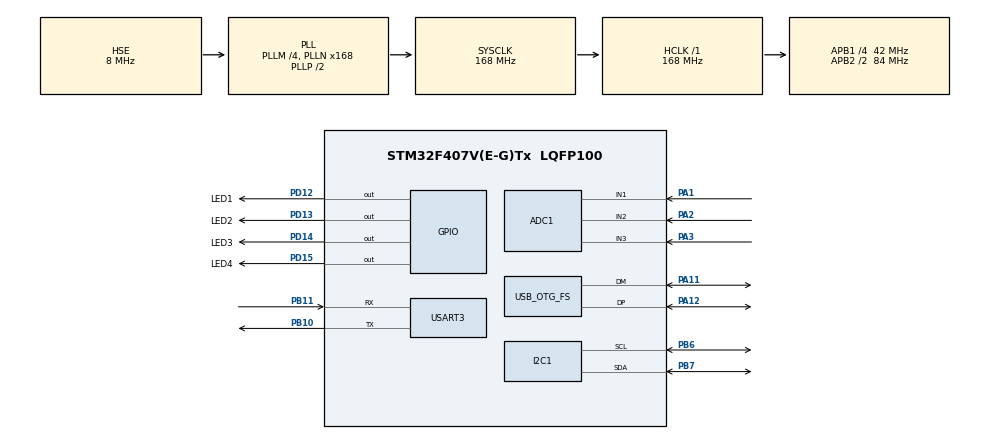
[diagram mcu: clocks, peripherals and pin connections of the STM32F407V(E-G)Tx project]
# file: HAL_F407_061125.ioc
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ADC1.Channel-0\#ChannelRegularConversion=ADC_CHANNEL_1
ADC1.Channel-1\#ChannelRegularConversion=ADC_CHANNEL_2
ADC1.Channel-2\#ChannelRegularConversion=ADC_CHANNEL_3
ADC1.ContinuousConvMode=ENABLE
ADC1.DMAContinuousRequests=ENABLE
ADC1.NbrOfConversion=3
ADC1.NbrOfConversionFlag=1
ADC1.Rank-0\#ChannelRegularConversion=1
ADC1.Rank-1\#ChannelRegularConversion=2
ADC1.Rank-2\#ChannelRegularConversion=3
ADC1.SamplingTime-0\#ChannelRegularConversion=ADC_SAMPLETIME_144CYCLES
ADC1.SamplingTime-1\#ChannelRegularConversion=ADC_SAMPLETIME_144CYCLES
ADC1.SamplingTime-2\#ChannelRegularConversion=ADC_SAMPLETIME_144CYCLES
ADC1.ScanConvMode=ENABLE
ADC1.master=1
Dma.ADC1.1.Direction=DMA_PERIPH_TO_MEMORY
Dma.ADC1.1.FIFOMode=DMA_FIFOMODE_DISABLE
Dma.ADC1.1.Instance=DMA2_Stream0
Dma.ADC1.1.MemDataAlignment=DMA_MDATAALIGN_HALFWORD
Dma.ADC1.1.MemInc=DMA_MINC_ENABLE
Dma.ADC1.1.Mode=DMA_CIRCULAR
Dma.ADC1.1.PeriphDataAlignment=DMA_PDATAALIGN_HALFWORD
Dma.ADC1.1.PeriphInc=DMA_PINC_DISABLE
Dma.ADC1.1.Priority=DMA_PRIORITY_LOW
Dma.Request0=USART3_TX
Dma.Request1=ADC1
Dma.USART3_TX.0.Direction=DMA_MEMORY_TO_PERIPH
Dma.USART3_TX.0.FIFOMode=DMA_FIFOMODE_DISABLE
Dma.USART3_TX.0.Instance=DMA1_Stream3
Dma.USART3_TX.0.MemDataAlignment=DMA_MDATAALIGN_BYTE
Dma.USART3_TX.0.MemInc=DMA_MINC_ENABLE
Dma.USART3_TX.0.Mode=DMA_NORMAL
Dma.USART3_TX.0.PeriphDataAlignment=DMA_PDATAALIGN_BYTE
Dma.USART3_TX.0.PeriphInc=DMA_PINC_DISABLE
Dma.USART3_TX.0.Priority=DMA_PRIORITY_LOW
FREERTOS.Tasks01=defaultTask,0,128,StartDefaultTask,Default,NULL,Dynamic,NULL,NULL
Mcu.Family=STM32F4
Mcu.Name=STM32F407V(E-G)Tx
Mcu.Package=LQFP100
NVIC.DMA1_Stream3_IRQn=true\:5\:0\:false\:false\:true\:true\:false\:true\:true
NVIC.DMA2_Stream0_IRQn=true\:5\:0\:false\:false\:true\:true\:false\:true\:true
NVIC.OTG_FS_IRQn=true\:5\:0\:false\:false\:true\:true\:false\:true\:true
NVIC.PriorityGroup=NVIC_PRIORITYGROUP_4
NVIC.TIM1_UP_TIM10_IRQn=true\:5\:0\:false\:false\:true\:true\:true\:true\:true
NVIC.TIM3_IRQn=true\:15\:0\:false\:false\:true\:false\:false\:true\:true
NVIC.TimeBase=TIM3_IRQn
NVIC.TimeBaseIP=TIM3
NVIC.USART3_IRQn=true\:5\:0\:false\:false\:true\:true\:true\:true\:true
PA1.Signal=ADCx_IN1
PA11.Mode=Device_Only
PA11.Signal=USB_OTG_FS_DM
PA12.Mode=Device_Only
PA12.Signal=USB_OTG_FS_DP
PA13.Mode=Serial_Wire
PA13.Signal=SYS_JTMS-SWDIO
PA14.Mode=Serial_Wire
PA14.Signal=SYS_JTCK-SWCLK
PA2.Signal=ADCx_IN2
PA3.Signal=ADCx_IN3
PB10.Mode=Asynchronous
PB10.Signal=USART3_TX
PB11.Mode=Asynchronous
PB11.Signal=USART3_RX
PB6.Mode=I2C
PB6.Signal=I2C1_SCL
PB7.Mode=I2C
PB7.Signal=I2C1_SDA
PD12.GPIO_Label=LED1
PD12.Signal=GPIO_Output
PD13.GPIO_Label=LED2
PD13.Signal=GPIO_Output
PD14.GPIO_Label=LED3
PD14.Signal=GPIO_Output
PD15.GPIO_Label=LED4
PD15.Signal=GPIO_Output
PH0-OSC_IN.Mode=HSE-External-Oscillator
PH0-OSC_IN.Signal=RCC_OSC_IN
PH1-OSC_OUT.Mode=HSE-External-Oscillator
PH1-OSC_OUT.Signal=RCC_OSC_OUT
ProjectManager.HeapSize=0x200
ProjectManager.StackSize=0x400
ProjectManager.TargetToolchain=MDK-ARM V5.32
RCC.48MHZClocksFreq_Value=48000000
RCC.AHBFreq_Value=168000000
RCC.APB1CLKDivider=RCC_HCLK_DIV4
RCC.APB1Freq_Value=42000000
RCC.APB1TimFreq_Value=84000000
RCC.APB2CLKDivider=RCC_HCLK_DIV2
RCC.APB2Freq_Value=84000000
RCC.APB2TimFreq_Value=168000000
RCC.CortexFreq_Value=168000000
RCC.HCLKFreq_Value=168000000
RCC.HSE_VALUE=8000000
RCC.HSI_VALUE=16000000
RCC.LSE_VALUE=32768
RCC.PLLM=4
RCC.PLLN=168
RCC.PLLQ=7
RCC.SYSCLKFreq_VALUE=168000000
RCC.SYSCLKSource=RCC_SYSCLKSOURCE_PLLCLK
RCC.VCOOutputFreq_Value=336000000
SH.ADCx_IN1.0=ADC1_IN1,IN1
SH.ADCx_IN2.0=ADC1_IN2,IN2
SH.ADCx_IN3.0=ADC1_IN3,IN3
TIM1.AutoReloadPreload=TIM_AUTORELOAD_PRELOAD_ENABLE
TIM1.Period=999
TIM1.Prescaler=16799
USART3.VirtualMode=VM_ASYNC
USB_DEVICE.CLASS_NAME_FS=CDC
USB_DEVICE.VirtualMode-CDC_FS=Cdc
USB_DEVICE.VirtualModeFS=Cdc_FS
USB_OTG_FS.VirtualMode=Device_Only
VP_FREERTOS_VS_CMSIS_V1.Mode=CMSIS_V1
VP_RTC_VS_RTC_Activate.Mode=RTC_Enabled
VP_RTC_VS_RTC_Calendar.Mode=RTC_Calendar
VP_SYS_VS_tim3.Mode=TIM3
VP_TIM1_VS_ClockSourceINT.Mode=Internal
VP_USB_DEVICE_VS_USB_DEVICE_CDC_FS.Mode=CDC_FS
board=custom

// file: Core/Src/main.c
/* USER CODE BEGIN Header */
/**
  ******************************************************************************
  * @file           : main.c
  * @brief          : Main program body
  ******************************************************************************
  * @attention
  *
  * Copyright (c) 2025 STMicroelectronics.
  * All rights reserved.
  *
  * This software is licensed under terms that can be found in the LICENSE file
  * in the root directory of this software component.
  * If no LICENSE file comes with this software, it is provided AS-IS.
  *
  ******************************************************************************
  */
/* USER CODE END Header */
#include "main.h"
#include "cmsis_os.h"
#include "usb_device.h"

ADC_HandleTypeDef hadc1;
DMA_HandleTypeDef hdma_adc1;

I2C_HandleTypeDef hi2c1;

RTC_HandleTypeDef hrtc;

TIM_HandleTypeDef htim1;

UART_HandleTypeDef huart3;
DMA_HandleTypeDef hdma_usart3_tx;

osThreadId defaultTaskHandle;

void SystemClock_Config(void);
static void MX_GPIO_Init(void);
static void MX_DMA_Init(void);
static void MX_I2C1_Init(void);
static void MX_USART3_UART_Init(void);
static void MX_ADC1_Init(void);
static void MX_RTC_Init(void);
static void MX_TIM1_Init(void);
void StartDefaultTask(void const * argument);

int main(void)
{
  /* USER CODE BEGIN 1 */

	SCB->CPACR|=(0xF<<20);
	__DSB();
	__ISB();

  /* USER CODE END 1 */

  /* MCU Configuration--------------------------------------------------------*/

  /* Reset of all peripherals, Initializes the Flash interface and the Systick. */
  HAL_Init();

  /* Configure the system clock */
  SystemClock_Config();

  /* Initialize all configured peripherals */
  MX_GPIO_Init();
  MX_DMA_Init();
  MX_I2C1_Init();
  MX_USART3_UART_Init();
  MX_ADC1_Init();
  MX_RTC_Init();
  MX_TIM1_Init();
  /* USER CODE BEGIN 2 */

	MX_USB_DEVICE_Init();
	HAL_ADC_Start_DMA(&hadc1,(uint32_t*)adc_value.adcValues,3);

	xTaskCreate(Task1,"Task1",256,NULL,5,NULL);
	xTaskCreate(TaskAdc,"TaskAdc",256,NULL,5,NULL);

	vTaskStartScheduler();

  /* USER CODE END 2 */

  /* Create the thread(s) */
  /* definition and creation of defaultTask */
  osThreadDef(defaultTask, StartDefaultTask, osPriorityNormal, 0, 128);
  defaultTaskHandle = osThreadCreate(osThread(defaultTask), NULL);

  /* Start scheduler */
  osKernelStart();

  /* We should never get here as control is now taken by the scheduler */
  /* Infinite loop */
  while (1)
  {

  }
}

void SystemClock_Config(void)
{
  RCC_OscInitTypeDef RCC_OscInitStruct = {0};
  RCC_ClkInitTypeDef RCC_ClkInitStruct = {0};

  /** Configure the main internal regulator output voltage
  */
  __HAL_RCC_PWR_CLK_ENABLE();
  __HAL_PWR_VOLTAGESCALING_CONFIG(PWR_REGULATOR_VOLTAGE_SCALE1);

  /** Initializes the RCC Oscillators according to the specified parameters
  * in the RCC_OscInitTypeDef structure.
  */
  RCC_OscInitStruct.OscillatorType = RCC_OSCILLATORTYPE_LSI|RCC_OSCILLATORTYPE_HSE;
  RCC_OscInitStruct.HSEState = RCC_HSE_ON;
  RCC_OscInitStruct.LSIState = RCC_LSI_ON;
  RCC_OscInitStruct.PLL.PLLState = RCC_PLL_ON;
  RCC_OscInitStruct.PLL.PLLSource = RCC_PLLSOURCE_HSE;
  RCC_OscInitStruct.PLL.PLLM = 4;
  RCC_OscInitStruct.PLL.PLLN = 168;
  RCC_OscInitStruct.PLL.PLLP = RCC_PLLP_DIV2;
  RCC_OscInitStruct.PLL.PLLQ = 7;
  if (HAL_RCC_OscConfig(&RCC_OscInitStruct) != HAL_OK)
  {
    Error_Handler();
  }

  /** Initializes the CPU, AHB and APB buses clocks
  */
  RCC_ClkInitStruct.ClockType = RCC_CLOCKTYPE_HCLK|RCC_CLOCKTYPE_SYSCLK
                              |RCC_CLOCKTYPE_PCLK1|RCC_CLOCKTYPE_PCLK2;
  RCC_ClkInitStruct.SYSCLKSource = RCC_SYSCLKSOURCE_PLLCLK;
  RCC_ClkInitStruct.AHBCLKDivider = RCC_SYSCLK_DIV1;
  RCC_ClkInitStruct.APB1CLKDivider = RCC_HCLK_DIV4;
  RCC_ClkInitStruct.APB2CLKDivider = RCC_HCLK_DIV2;

  if (HAL_RCC_ClockConfig(&RCC_ClkInitStruct, FLASH_LATENCY_5) != HAL_OK)
  {
    Error_Handler();
  }
}

static void MX_ADC1_Init(void)
{

  ADC_ChannelConfTypeDef sConfig = {0};

  /** Configure the global features of the ADC (Clock, Resolution, Data Alignment and number of conversion)
  */
  hadc1.Instance = ADC1;
  hadc1.Init.ClockPrescaler = ADC_CLOCK_SYNC_PCLK_DIV4;
  hadc1.Init.Resolution = ADC_RESOLUTION_12B;
  hadc1.Init.ScanConvMode = ENABLE;
  hadc1.Init.ContinuousConvMode = ENABLE;
  hadc1.Init.DiscontinuousConvMode = DISABLE;
  hadc1.Init.ExternalTrigConvEdge = ADC_EXTERNALTRIGCONVEDGE_NONE;
  hadc1.Init.ExternalTrigConv = ADC_SOFTWARE_START;
  hadc1.Init.DataAlign = ADC_DATAALIGN_RIGHT;
  hadc1.Init.NbrOfConversion = 3;
  hadc1.Init.DMAContinuousRequests = ENABLE;
  hadc1.Init.EOCSelection = ADC_EOC_SINGLE_CONV;
  if (HAL_ADC_Init(&hadc1) != HAL_OK)
  {
    Error_Handler();
  }

  /** Configure for the selected ADC regular channel its corresponding rank in the sequencer and its sample time.
  */
  sConfig.Channel = ADC_CHANNEL_1;
  sConfig.Rank = 1;
  sConfig.SamplingTime = ADC_SAMPLETIME_144CYCLES;
  if (HAL_ADC_ConfigChannel(&hadc1, &sConfig) != HAL_OK)
  {
    Error_Handler();
  }

  /** Configure for the selected ADC regular channel its corresponding rank in the sequencer and its sample time.
  */
  sConfig.Channel = ADC_CHANNEL_2;
  sConfig.Rank = 2;
  if (HAL_ADC_ConfigChannel(&hadc1, &sConfig) != HAL_OK)
  {
    Error_Handler();
  }

  /** Configure for the selected ADC regular channel its corresponding rank in the sequencer and its sample time.
  */
  sConfig.Channel = ADC_CHANNEL_3;
  sConfig.Rank = 3;
  if (HAL_ADC_ConfigChannel(&hadc1, &sConfig) != HAL_OK)
  {
    Error_Handler();
  }

}

static void MX_I2C1_Init(void)
{

  hi2c1.Instance = I2C1;
  hi2c1.Init.ClockSpeed = 100000;
  hi2c1.Init.DutyCycle = I2C_DUTYCYCLE_2;
  hi2c1.Init.OwnAddress1 = 0;
  hi2c1.Init.AddressingMode = I2C_ADDRESSINGMODE_7BIT;
  hi2c1.Init.DualAddressMode = I2C_DUALADDRESS_DISABLE;
  hi2c1.Init.OwnAddress2 = 0;
  hi2c1.Init.GeneralCallMode = I2C_GENERALCALL_DISABLE;
  hi2c1.Init.NoStretchMode = I2C_NOSTRETCH_DISABLE;
  if (HAL_I2C_Init(&hi2c1) != HAL_OK)
  {
    Error_Handler();
  }

}

static void MX_RTC_Init(void)
{

  RTC_TimeTypeDef sTime = {0};
  RTC_DateTypeDef sDate = {0};

  /** Initialize RTC Only
  */
  hrtc.Instance = RTC;
  hrtc.Init.HourFormat = RTC_HOURFORMAT_24;
  hrtc.Init.AsynchPrediv = 127;
  hrtc.Init.SynchPrediv = 255;
  hrtc.Init.OutPut = RTC_OUTPUT_DISABLE;
  hrtc.Init.OutPutPolarity = RTC_OUTPUT_POLARITY_HIGH;
  hrtc.Init.OutPutType = RTC_OUTPUT_TYPE_OPENDRAIN;
  if (HAL_RTC_Init(&hrtc) != HAL_OK)
  {
    Error_Handler();
  }

  /** Initialize RTC and set the Time and Date
  */
  sTime.Hours = 0x0;
  sTime.Minutes = 0x0;
  sTime.Seconds = 0x0;
  sTime.DayLightSaving = RTC_DAYLIGHTSAVING_NONE;
  sTime.StoreOperation = RTC_STOREOPERATION_RESET;
  if (HAL_RTC_SetTime(&hrtc, &sTime, RTC_FORMAT_BCD) != HAL_OK)
  {
    Error_Handler();
  }
  sDate.WeekDay = RTC_WEEKDAY_MONDAY;
  sDate.Month = RTC_MONTH_JANUARY;
  sDate.Date = 0x1;
  sDate.Year = 0x0;

  if (HAL_RTC_SetDate(&hrtc, &sDate, RTC_FORMAT_BCD) != HAL_OK)
  {
    Error_Handler();
  }

}

static void MX_TIM1_Init(void)
{

  TIM_ClockConfigTypeDef sClockSourceConfig = {0};
  TIM_MasterConfigTypeDef sMasterConfig = {0};

  htim1.Instance = TIM1;
  htim1.Init.Prescaler = 16799;
  htim1.Init.CounterMode = TIM_COUNTERMODE_UP;
  htim1.Init.Period = 999;
  htim1.Init.ClockDivision = TIM_CLOCKDIVISION_DIV1;
  htim1.Init.RepetitionCounter = 0;
  htim1.Init.AutoReloadPreload = TIM_AUTORELOAD_PRELOAD_ENABLE;
  if (HAL_TIM_Base_Init(&htim1) != HAL_OK)
  {
    Error_Handler();
  }
  sClockSourceConfig.ClockSource = TIM_CLOCKSOURCE_INTERNAL;
  if (HAL_TIM_ConfigClockSource(&htim1, &sClockSourceConfig) != HAL_OK)
  {
    Error_Handler();
  }
  sMasterConfig.MasterOutputTrigger = TIM_TRGO_RESET;
  sMasterConfig.MasterSlaveMode = TIM_MASTERSLAVEMODE_DISABLE;
  if (HAL_TIMEx_MasterConfigSynchronization(&htim1, &sMasterConfig) != HAL_OK)
  {
    Error_Handler();
  }

}

static void MX_USART3_UART_Init(void)
{

  huart3.Instance = USART3;
  huart3.Init.BaudRate = 115200;
  huart3.Init.WordLength = UART_WORDLENGTH_8B;
  huart3.Init.StopBits = UART_STOPBITS_1;
  huart3.Init.Parity = UART_PARITY_NONE;
  huart3.Init.Mode = UART_MODE_TX_RX;
  huart3.Init.HwFlowCtl = UART_HWCONTROL_NONE;
  huart3.Init.OverSampling = UART_OVERSAMPLING_16;
  if (HAL_UART_Init(&huart3) != HAL_OK)
  {
    Error_Handler();
  }

}

static void MX_DMA_Init(void)
{

  /* DMA controller clock enable */
  __HAL_RCC_DMA1_CLK_ENABLE();
  __HAL_RCC_DMA2_CLK_ENABLE();

  /* DMA interrupt init */
  /* DMA1_Stream3_IRQn interrupt configuration */
  HAL_NVIC_SetPriority(DMA1_Stream3_IRQn, 5, 0);
  HAL_NVIC_EnableIRQ(DMA1_Stream3_IRQn);
  /* DMA2_Stream0_IRQn interrupt configuration */
  HAL_NVIC_SetPriority(DMA2_Stream0_IRQn, 5, 0);
  HAL_NVIC_EnableIRQ(DMA2_Stream0_IRQn);

}

static void MX_GPIO_Init(void)
{
  GPIO_InitTypeDef GPIO_InitStruct = {0};

  /* GPIO Ports Clock Enable */
  __HAL_RCC_GPIOH_CLK_ENABLE();
  __HAL_RCC_GPIOA_CLK_ENABLE();
  __HAL_RCC_GPIOB_CLK_ENABLE();
  __HAL_RCC_GPIOD_CLK_ENABLE();

  /*Configure GPIO pin Output Level */
  HAL_GPIO_WritePin(GPIOD, LED1_Pin|LED2_Pin|LED3_Pin|LED4_Pin, GPIO_PIN_RESET);

  /*Configure GPIO pins : LED1_Pin LED2_Pin LED3_Pin LED4_Pin */
  GPIO_InitStruct.Pin = LED1_Pin|LED2_Pin|LED3_Pin|LED4_Pin;
  GPIO_InitStruct.Mode = GPIO_MODE_OUTPUT_PP;
  GPIO_InitStruct.Pull = GPIO_NOPULL;
  GPIO_InitStruct.Speed = GPIO_SPEED_FREQ_LOW;
  HAL_GPIO_Init(GPIOD, &GPIO_InitStruct);

}

void StartDefaultTask(void const * argument)
{
  /* init code for USB_DEVICE */
  MX_USB_DEVICE_Init();
  for(;;)
  {
    osDelay(1);
  }
}

void HAL_TIM_PeriodElapsedCallback(TIM_HandleTypeDef *htim)
{
  if (htim->Instance == TIM3) {
    HAL_IncTick();
  }
}

void Error_Handler(void)
{
  __disable_irq();
  while (1)
  {
  }
}
